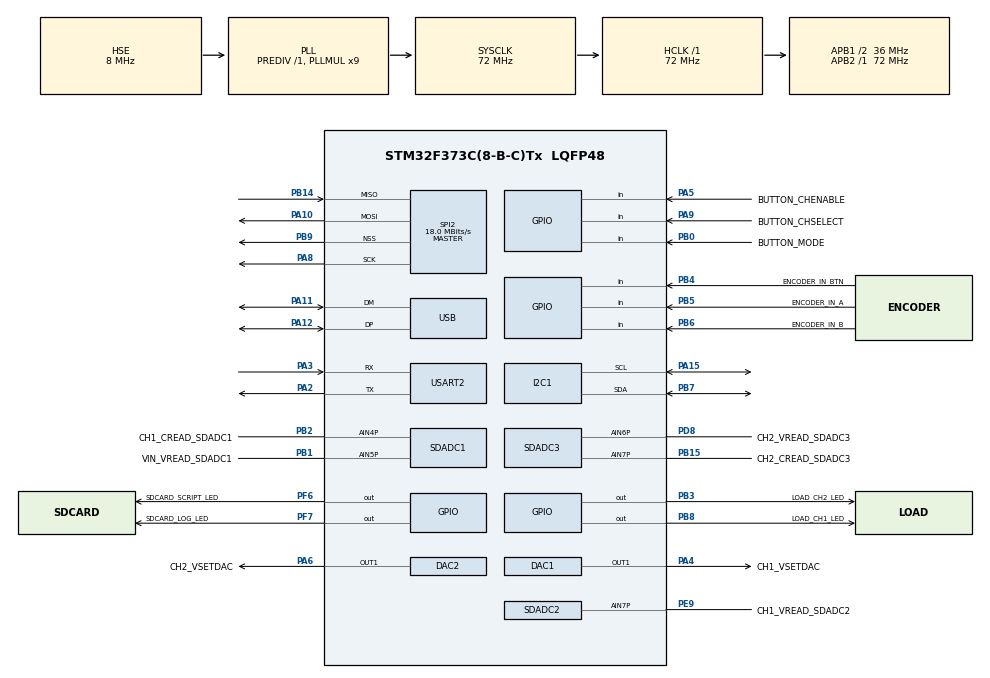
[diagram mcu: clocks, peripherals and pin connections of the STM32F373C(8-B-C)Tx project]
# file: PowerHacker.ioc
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ADC1.Channel-2\#ChannelRegularConversion=ADC_CHANNEL_TEMPSENSOR
ADC1.NbrOfConversion=1
ADC1.NbrOfConversionFlag=1
ADC1.Rank-2\#ChannelRegularConversion=1
ADC1.SamplingTime-2\#ChannelRegularConversion=ADC_SAMPLETIME_1CYCLE_5
ADC1.master=1
Mcu.Family=STM32F3
Mcu.Name=STM32F373C(8-B-C)Tx
Mcu.Package=LQFP48
NVIC.PriorityGroup=NVIC_PRIORITYGROUP_4
NVIC.TIM19_IRQn=true\:0\:0\:false\:false\:true\:false\:true
NVIC.TimeBase=TIM19_IRQn
NVIC.TimeBaseIP=TIM19
NVIC.USB_LP_IRQn=true\:0\:0\:false\:false\:true\:false\:true
PA10.Mode=Full_Duplex_Master
PA10.Signal=SPI2_MOSI
PA11.Mode=Device
PA11.Signal=USB_DM
PA12.Mode=Device
PA12.Signal=USB_DP
PA13.Mode=Serial_Wire
PA13.Signal=SYS_JTMS-SWDIO
PA14.Mode=Serial_Wire
PA14.Signal=SYS_JTCK-SWCLK
PA15.Mode=I2C
PA15.Signal=I2C1_SCL
PA2.Mode=Asynchronous
PA2.Signal=USART2_TX
PA3.Mode=Asynchronous
PA3.Signal=USART2_RX
PA4.GPIO_Label=CH1_VSETDAC
PA4.Signal=COMP_DAC11_group
PA5.GPIO_Label=BUTTON_CHENABLE
PA5.GPIO_PuPd=GPIO_PULLUP
PA5.Signal=GPIO_Input
PA6.GPIO_Label=CH2_VSETDAC
PA6.Signal=COMP_DAC21_group
PA8.Mode=Full_Duplex_Master
PA8.Signal=SPI2_SCK
PA9.GPIO_Label=BUTTON_CHSELECT
PA9.GPIO_PuPd=GPIO_PULLUP
PA9.Signal=GPIO_Input
PB0.GPIO_Label=BUTTON_MODE
PB0.GPIO_PuPd=GPIO_PULLUP
PB0.Signal=GPIO_Input
PB1.GPIO_Label=VIN_VREAD_SDADC1
PB1.Mode=IN5-Single-Ended
PB1.Signal=SDADC1_AIN5P
PB14.Mode=Full_Duplex_Master
PB14.Signal=SPI2_MISO
PB15.GPIO_Label=CH2_CREAD_SDADC3
PB15.Mode=IN7-Single-Ended
PB15.Signal=SDADC3_AIN7P
PB2.GPIO_Label=CH1_CREAD_SDADC1
PB2.Mode=IN4-Single-Ended
PB2.Signal=SDADC1_AIN4P
PB3.GPIO_Label=LOAD_CH2_LED
PB3.Signal=GPIO_Output
PB4.GPIO_Label=ENCODER_IN_BTN
PB4.GPIO_PuPd=GPIO_PULLUP
PB4.Signal=GPIO_Input
PB5.GPIO_Label=ENCODER_IN_A
PB5.GPIO_PuPd=GPIO_PULLUP
PB5.Signal=GPIO_Input
PB6.GPIO_Label=ENCODER_IN_B
PB6.GPIO_PuPd=GPIO_PULLUP
PB6.Signal=GPIO_Input
PB7.Mode=I2C
PB7.Signal=I2C1_SDA
PB8.GPIO_Label=LOAD_CH1_LED
PB8.Signal=GPIO_Output
PB9.Mode=NSS_Signal_Hard_Output
PB9.Signal=SPI2_NSS
PC14-OSC32_IN.Mode=LSE-External-Oscillator
PC14-OSC32_IN.Signal=RCC_OSC32_IN
PC15-OSC32_OUT.Mode=LSE-External-Oscillator
PC15-OSC32_OUT.Signal=RCC_OSC32_OUT
PD8.GPIO_Label=CH2_VREAD_SDADC3
PD8.Mode=IN6-Single-Ended
PD8.Signal=SDADC3_AIN6P
PE9.GPIO_Label=CH1_VREAD_SDADC2
PE9.Mode=IN7-Single-Ended
PE9.Signal=SDADC2_AIN7P
PF0-OSC_IN.Mode=HSE-External-Oscillator
PF0-OSC_IN.Signal=RCC_OSC_IN
PF1-OSC_OUT.Mode=HSE-External-Oscillator
PF1-OSC_OUT.Signal=RCC_OSC_OUT
PF6.GPIO_Label=SDCARD_SCRIPT_LED
PF6.Signal=GPIO_Output
PF7.GPIO_Label=SDCARD_LOG_LED
PF7.Signal=GPIO_Output
ProjectManager.HeapSize=0x200
ProjectManager.StackSize=0x400
ProjectManager.TargetToolchain=STM32CubeIDE
RCC.AHBFreq_Value=72000000
RCC.APB1CLKDivider=RCC_HCLK_DIV2
RCC.APB1Freq_Value=36000000
RCC.APB1TimFreq_Value=72000000
RCC.APB2Freq_Value=72000000
RCC.APB2TimFreq_Value=72000000
RCC.CortexFreq_Value=72000000
RCC.HCLKFreq_Value=72000000
RCC.HSE_VALUE=8000000
RCC.HSI_VALUE=8000000
RCC.PLLMUL=RCC_PLL_MUL9
RCC.PRESCALERUSB=RCC_USBCLKSOURCE_PLL_DIV1_5
RCC.RTCClockSelection=RCC_RTCCLKSOURCE_LSE
RCC.SDADCPresc=RCC_SDADCSYSCLK_DIV12
RCC.SYSCLKFreq_VALUE=72000000
RCC.SYSCLKSource=RCC_SYSCLKSOURCE_PLLCLK
RCC.USBFreq_Value=48000000
SDADC1.NbrOfConversionFlag=1
SDADC2.NbrOfConversionFlag=1
SDADC3.NbrOfConversionFlag=1
SH.COMP_DAC11_group.0=DAC1_OUT1,DAC_OUT1
SH.COMP_DAC21_group.0=DAC2_OUT1,DAC_OUT1
SPI2.CalculateBaudRate=18.0 MBits/s
SPI2.Direction=SPI_DIRECTION_2LINES
SPI2.Mode=SPI_MODE_MASTER
SPI2.VirtualNSS=VM_NSSHARD
SPI2.VirtualType=VM_MASTER
USART2.VirtualMode-Asynchronous=VM_ASYNC
USB_DEVICE.CLASS_NAME_FS=CDC
USB_DEVICE.LANGID_STRING=1033
USB_DEVICE.MANUFACTURER_STRING=ArduCore
USB_DEVICE.PRODUCT_STRING_CDC_FS=ArduCore PowerHacker
USB_DEVICE.VirtualMode=Cdc
USB_DEVICE.VirtualModeFS=Cdc_FS
VP_ADC1_TempSens_Input.Mode=IN-TempSens
VP_RTC_VS_RTC_Activate.Mode=RTC_Enabled
VP_SDADC1_CONF0.Mode=ConfigZero
VP_SDADC2_CONF1.Mode=ConfigUn
VP_SYS_VS_tim19.Mode=TIM19
VP_USB_DEVICE_VS_USB_DEVICE_CDC_FS.Mode=CDC_FS
board=custom

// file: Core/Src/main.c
/* USER CODE BEGIN Header */
/**
  ******************************************************************************
  * @file           : main.c
  * @brief          : Main program body
  ******************************************************************************
  * @attention
  *
  * <h2><center>&copy; Copyright (c) 2020 STMicroelectronics.
  * All rights reserved.</center></h2>
  *
  * This software component is licensed by ST under BSD 3-Clause license,
  * the "License"; You may not use this file except in compliance with the
  * License. You may obtain a copy of the License at:
  *                        opensource.org/licenses/BSD-3-Clause
  *
  ******************************************************************************
  */
/* USER CODE END Header */
#include "main.h"
#include "usb_device.h"

/* USER CODE BEGIN Includes */
#include <entryPointDefinition.hpp>
/* USER CODE END Includes */

ADC_HandleTypeDef hadc1;

DAC_HandleTypeDef hdac1;
DAC_HandleTypeDef hdac2;

I2C_HandleTypeDef hi2c1;

RTC_HandleTypeDef hrtc;

SDADC_HandleTypeDef hsdadc1;
SDADC_HandleTypeDef hsdadc2;
SDADC_HandleTypeDef hsdadc3;

SPI_HandleTypeDef hspi2;

UART_HandleTypeDef huart2;

void SystemClock_Config(void);
static void MX_GPIO_Init(void);
static void MX_I2C1_Init(void);
static void MX_RTC_Init(void);
static void MX_SDADC1_Init(void);
static void MX_ADC1_Init(void);
static void MX_DAC1_Init(void);
static void MX_DAC2_Init(void);
static void MX_SDADC2_Init(void);
static void MX_SPI2_Init(void);
static void MX_SDADC3_Init(void);
static void MX_USART2_UART_Init(void);

int main(void)
{

  /* MCU Configuration--------------------------------------------------------*/

  /* Reset of all peripherals, Initializes the Flash interface and the Systick. */
  HAL_Init();

  /* Configure the system clock */
  SystemClock_Config();

  /* Initialize all configured peripherals */
  MX_GPIO_Init();
  MX_I2C1_Init();
  MX_RTC_Init();
  MX_SDADC1_Init();
  MX_ADC1_Init();
  MX_DAC1_Init();
  MX_DAC2_Init();
  MX_SDADC2_Init();
  MX_SPI2_Init();
  MX_USB_DEVICE_Init();
  MX_SDADC3_Init();
  MX_USART2_UART_Init();
  /* USER CODE BEGIN 2 */
  HAL_DAC_Start(&hdac1, DAC_CHANNEL_1);
  HAL_DAC_SetValue(&hdac1, DAC_CHANNEL_1, DAC_ALIGN_12B_L, 0x100); //TODO: Debug DAC values
  entryPointSetup();
  /* USER CODE END 2 */

  /* Infinite loop */
  for(;;)
  {

    /* USER CODE BEGIN 3 */
	  entryPointLoop();

  }
  /* USER CODE END 3 */
}

void SystemClock_Config(void)
{
  RCC_OscInitTypeDef RCC_OscInitStruct = {0};
  RCC_ClkInitTypeDef RCC_ClkInitStruct = {0};
  RCC_PeriphCLKInitTypeDef PeriphClkInit = {0};

  /** Configure LSE Drive Capability
  */
  HAL_PWR_EnableBkUpAccess();
  __HAL_RCC_LSEDRIVE_CONFIG(RCC_LSEDRIVE_LOW);
  /** Initializes the RCC Oscillators according to the specified parameters
  * in the RCC_OscInitTypeDef structure.
  */
  RCC_OscInitStruct.OscillatorType = RCC_OSCILLATORTYPE_HSI|RCC_OSCILLATORTYPE_HSE
                              |RCC_OSCILLATORTYPE_LSE;
  RCC_OscInitStruct.HSEState = RCC_HSE_ON;
  RCC_OscInitStruct.HSEPredivValue = RCC_HSE_PREDIV_DIV1;
  RCC_OscInitStruct.LSEState = RCC_LSE_ON;
  RCC_OscInitStruct.HSIState = RCC_HSI_ON;
  RCC_OscInitStruct.HSICalibrationValue = RCC_HSICALIBRATION_DEFAULT;
  RCC_OscInitStruct.PLL.PLLState = RCC_PLL_ON;
  RCC_OscInitStruct.PLL.PLLSource = RCC_PLLSOURCE_HSE;
  RCC_OscInitStruct.PLL.PLLMUL = RCC_PLL_MUL9;
  if (HAL_RCC_OscConfig(&RCC_OscInitStruct) != HAL_OK)
  {
    Error_Handler();
  }
  /** Initializes the CPU, AHB and APB buses clocks
  */
  RCC_ClkInitStruct.ClockType = RCC_CLOCKTYPE_HCLK|RCC_CLOCKTYPE_SYSCLK
                              |RCC_CLOCKTYPE_PCLK1|RCC_CLOCKTYPE_PCLK2;
  RCC_ClkInitStruct.SYSCLKSource = RCC_SYSCLKSOURCE_PLLCLK;
  RCC_ClkInitStruct.AHBCLKDivider = RCC_SYSCLK_DIV1;
  RCC_ClkInitStruct.APB1CLKDivider = RCC_HCLK_DIV2;
  RCC_ClkInitStruct.APB2CLKDivider = RCC_HCLK_DIV1;

  if (HAL_RCC_ClockConfig(&RCC_ClkInitStruct, FLASH_LATENCY_2) != HAL_OK)
  {
    Error_Handler();
  }
  PeriphClkInit.PeriphClockSelection = RCC_PERIPHCLK_USB|RCC_PERIPHCLK_USART2
                              |RCC_PERIPHCLK_I2C1|RCC_PERIPHCLK_RTC
                              |RCC_PERIPHCLK_ADC1|RCC_PERIPHCLK_SDADC;
  PeriphClkInit.Usart2ClockSelection = RCC_USART2CLKSOURCE_PCLK1;
  PeriphClkInit.I2c1ClockSelection = RCC_I2C1CLKSOURCE_HSI;
  PeriphClkInit.RTCClockSelection = RCC_RTCCLKSOURCE_LSE;
  PeriphClkInit.USBClockSelection = RCC_USBCLKSOURCE_PLL_DIV1_5;
  PeriphClkInit.SdadcClockSelection = RCC_SDADCSYSCLK_DIV12;
  PeriphClkInit.Adc1ClockSelection = RCC_ADC1PCLK2_DIV2;

  if (HAL_RCCEx_PeriphCLKConfig(&PeriphClkInit) != HAL_OK)
  {
    Error_Handler();
  }
  HAL_PWREx_EnableSDADC(PWR_SDADC_ANALOG1);
  HAL_PWREx_EnableSDADC(PWR_SDADC_ANALOG2);
  HAL_PWREx_EnableSDADC(PWR_SDADC_ANALOG3);
}

static void MX_ADC1_Init(void)
{

  ADC_ChannelConfTypeDef sConfig = {0};

  /** Common config
  */
  hadc1.Instance = ADC1;
  hadc1.Init.ScanConvMode = ADC_SCAN_DISABLE;
  hadc1.Init.ContinuousConvMode = DISABLE;
  hadc1.Init.DiscontinuousConvMode = DISABLE;
  hadc1.Init.ExternalTrigConv = ADC_SOFTWARE_START;
  hadc1.Init.DataAlign = ADC_DATAALIGN_RIGHT;
  hadc1.Init.NbrOfConversion = 1;
  if (HAL_ADC_Init(&hadc1) != HAL_OK)
  {
    Error_Handler();
  }
  /** Configure Regular Channel
  */
  sConfig.Channel = ADC_CHANNEL_TEMPSENSOR;
  sConfig.Rank = ADC_REGULAR_RANK_1;
  sConfig.SamplingTime = ADC_SAMPLETIME_1CYCLE_5;
  if (HAL_ADC_ConfigChannel(&hadc1, &sConfig) != HAL_OK)
  {
    Error_Handler();
  }

}

static void MX_DAC1_Init(void)
{

  DAC_ChannelConfTypeDef sConfig = {0};

  /** DAC Initialization
  */
  hdac1.Instance = DAC1;
  if (HAL_DAC_Init(&hdac1) != HAL_OK)
  {
    Error_Handler();
  }
  /** DAC channel OUT1 config
  */
  sConfig.DAC_Trigger = DAC_TRIGGER_NONE;
  sConfig.DAC_OutputBuffer = DAC_OUTPUTBUFFER_ENABLE;
  if (HAL_DAC_ConfigChannel(&hdac1, &sConfig, DAC_CHANNEL_1) != HAL_OK)
  {
    Error_Handler();
  }

}

static void MX_DAC2_Init(void)
{

  DAC_ChannelConfTypeDef sConfig = {0};

  /** DAC Initialization
  */
  hdac2.Instance = DAC2;
  if (HAL_DAC_Init(&hdac2) != HAL_OK)
  {
    Error_Handler();
  }
  /** DAC channel OUT1 config
  */
  sConfig.DAC_Trigger = DAC_TRIGGER_NONE;
  sConfig.DAC_OutputBuffer = DAC_OUTPUTBUFFER_ENABLE;
  if (HAL_DAC_ConfigChannel(&hdac2, &sConfig, DAC_CHANNEL_1) != HAL_OK)
  {
    Error_Handler();
  }

}

static void MX_I2C1_Init(void)
{

  hi2c1.Instance = I2C1;
  hi2c1.Init.Timing = 0x2000090E;
  hi2c1.Init.OwnAddress1 = 0;
  hi2c1.Init.AddressingMode = I2C_ADDRESSINGMODE_7BIT;
  hi2c1.Init.DualAddressMode = I2C_DUALADDRESS_DISABLE;
  hi2c1.Init.OwnAddress2 = 0;
  hi2c1.Init.OwnAddress2Masks = I2C_OA2_NOMASK;
  hi2c1.Init.GeneralCallMode = I2C_GENERALCALL_DISABLE;
  hi2c1.Init.NoStretchMode = I2C_NOSTRETCH_DISABLE;
  if (HAL_I2C_Init(&hi2c1) != HAL_OK)
  {
    Error_Handler();
  }
  /** Configure Analogue filter
  */
  if (HAL_I2CEx_ConfigAnalogFilter(&hi2c1, I2C_ANALOGFILTER_ENABLE) != HAL_OK)
  {
    Error_Handler();
  }
  /** Configure Digital filter
  */
  if (HAL_I2CEx_ConfigDigitalFilter(&hi2c1, 0) != HAL_OK)
  {
    Error_Handler();
  }

}

static void MX_RTC_Init(void)
{

  /** Initialize RTC Only
  */
  hrtc.Instance = RTC;
  hrtc.Init.HourFormat = RTC_HOURFORMAT_24;
  hrtc.Init.AsynchPrediv = 127;
  hrtc.Init.SynchPrediv = 255;
  hrtc.Init.OutPut = RTC_OUTPUT_DISABLE;
  hrtc.Init.OutPutPolarity = RTC_OUTPUT_POLARITY_HIGH;
  hrtc.Init.OutPutType = RTC_OUTPUT_TYPE_OPENDRAIN;
  if (HAL_RTC_Init(&hrtc) != HAL_OK)
  {
    Error_Handler();
  }

}

static void MX_SDADC1_Init(void)
{

  SDADC_ConfParamTypeDef ConfParamStruct = {0};

  /** Configure the SDADC low power mode, fast conversion mode,
  slow clock mode and SDADC1 reference voltage
  */
  hsdadc1.Instance = SDADC1;
  hsdadc1.Init.IdleLowPowerMode = SDADC_LOWPOWER_NONE;
  hsdadc1.Init.FastConversionMode = SDADC_FAST_CONV_DISABLE;
  hsdadc1.Init.SlowClockMode = SDADC_SLOW_CLOCK_DISABLE;
  hsdadc1.Init.ReferenceVoltage = SDADC_VREF_EXT;
  if (HAL_SDADC_Init(&hsdadc1) != HAL_OK)
  {
    Error_Handler();
  }
  /** Set parameters for SDADC configuration 0 Register
  */
  ConfParamStruct.InputMode = SDADC_INPUT_MODE_DIFF;
  ConfParamStruct.Gain = SDADC_GAIN_1;
  ConfParamStruct.CommonMode = SDADC_COMMON_MODE_VSSA;
  ConfParamStruct.Offset = 0;
  if (HAL_SDADC_PrepareChannelConfig(&hsdadc1, SDADC_CONF_INDEX_0, &ConfParamStruct) != HAL_OK)
  {
    Error_Handler();
  }

}

static void MX_SDADC2_Init(void)
{

  SDADC_ConfParamTypeDef ConfParamStruct = {0};

  /** Configure the SDADC low power mode, fast conversion mode,
  slow clock mode and SDADC1 reference voltage
  */
  hsdadc2.Instance = SDADC2;
  hsdadc2.Init.IdleLowPowerMode = SDADC_LOWPOWER_NONE;
  hsdadc2.Init.FastConversionMode = SDADC_FAST_CONV_DISABLE;
  hsdadc2.Init.SlowClockMode = SDADC_SLOW_CLOCK_DISABLE;
  hsdadc2.Init.ReferenceVoltage = SDADC_VREF_EXT;
  if (HAL_SDADC_Init(&hsdadc2) != HAL_OK)
  {
    Error_Handler();
  }
  /** Set parameters for SDADC configuration 1 Register
  */
  ConfParamStruct.InputMode = SDADC_INPUT_MODE_DIFF;
  ConfParamStruct.Gain = SDADC_GAIN_1;
  ConfParamStruct.CommonMode = SDADC_COMMON_MODE_VSSA;
  ConfParamStruct.Offset = 0;
  if (HAL_SDADC_PrepareChannelConfig(&hsdadc2, SDADC_CONF_INDEX_1, &ConfParamStruct) != HAL_OK)
  {
    Error_Handler();
  }

}

static void MX_SDADC3_Init(void)
{

  /** Configure the SDADC low power mode, fast conversion mode,
  slow clock mode and SDADC1 reference voltage
  */
  hsdadc3.Instance = SDADC3;
  hsdadc3.Init.IdleLowPowerMode = SDADC_LOWPOWER_NONE;
  hsdadc3.Init.FastConversionMode = SDADC_FAST_CONV_DISABLE;
  hsdadc3.Init.SlowClockMode = SDADC_SLOW_CLOCK_DISABLE;
  hsdadc3.Init.ReferenceVoltage = SDADC_VREF_EXT;
  if (HAL_SDADC_Init(&hsdadc3) != HAL_OK)
  {
    Error_Handler();
  }

}

static void MX_SPI2_Init(void)
{

  /* SPI2 parameter configuration*/
  hspi2.Instance = SPI2;
  hspi2.Init.Mode = SPI_MODE_MASTER;
  hspi2.Init.Direction = SPI_DIRECTION_2LINES;
  hspi2.Init.DataSize = SPI_DATASIZE_4BIT;
  hspi2.Init.CLKPolarity = SPI_POLARITY_LOW;
  hspi2.Init.CLKPhase = SPI_PHASE_1EDGE;
  hspi2.Init.NSS = SPI_NSS_HARD_OUTPUT;
  hspi2.Init.BaudRatePrescaler = SPI_BAUDRATEPRESCALER_2;
  hspi2.Init.FirstBit = SPI_FIRSTBIT_MSB;
  hspi2.Init.TIMode = SPI_TIMODE_DISABLE;
  hspi2.Init.CRCCalculation = SPI_CRCCALCULATION_DISABLE;
  hspi2.Init.CRCPolynomial = 7;
  hspi2.Init.CRCLength = SPI_CRC_LENGTH_DATASIZE;
  hspi2.Init.NSSPMode = SPI_NSS_PULSE_ENABLE;
  if (HAL_SPI_Init(&hspi2) != HAL_OK)
  {
    Error_Handler();
  }

}

static void MX_USART2_UART_Init(void)
{

  huart2.Instance = USART2;
  huart2.Init.BaudRate = 38400;
  huart2.Init.WordLength = UART_WORDLENGTH_8B;
  huart2.Init.StopBits = UART_STOPBITS_1;
  huart2.Init.Parity = UART_PARITY_NONE;
  huart2.Init.Mode = UART_MODE_TX_RX;
  huart2.Init.HwFlowCtl = UART_HWCONTROL_NONE;
  huart2.Init.OverSampling = UART_OVERSAMPLING_16;
  huart2.Init.OneBitSampling = UART_ONE_BIT_SAMPLE_DISABLE;
  huart2.AdvancedInit.AdvFeatureInit = UART_ADVFEATURE_NO_INIT;
  if (HAL_UART_Init(&huart2) != HAL_OK)
  {
    Error_Handler();
  }

}

static void MX_GPIO_Init(void)
{
  GPIO_InitTypeDef GPIO_InitStruct = {0};

  /* GPIO Ports Clock Enable */
  __HAL_RCC_GPIOC_CLK_ENABLE();
  __HAL_RCC_GPIOF_CLK_ENABLE();
  __HAL_RCC_GPIOA_CLK_ENABLE();
  __HAL_RCC_GPIOB_CLK_ENABLE();
  __HAL_RCC_GPIOE_CLK_ENABLE();
  __HAL_RCC_GPIOD_CLK_ENABLE();

  /*Configure GPIO pin Output Level */
  HAL_GPIO_WritePin(GPIOF, SDCARD_SCRIPT_LED_Pin|SDCARD_LOG_LED_Pin, GPIO_PIN_RESET);

  /*Configure GPIO pin Output Level */
  HAL_GPIO_WritePin(GPIOB, LOAD_CH2_LED_Pin|LOAD_CH1_LED_Pin, GPIO_PIN_RESET);

  /*Configure GPIO pins : BUTTON_CHENABLE_Pin BUTTON_CHSELECT_Pin */
  GPIO_InitStruct.Pin = BUTTON_CHENABLE_Pin|BUTTON_CHSELECT_Pin;
  GPIO_InitStruct.Mode = GPIO_MODE_INPUT;
  GPIO_InitStruct.Pull = GPIO_PULLUP;
  HAL_GPIO_Init(GPIOA, &GPIO_InitStruct);

  /*Configure GPIO pins : BUTTON_MODE_Pin ENCODER_IN_BTN_Pin ENCODER_IN_A_Pin ENCODER_IN_B_Pin */
  GPIO_InitStruct.Pin = BUTTON_MODE_Pin|ENCODER_IN_BTN_Pin|ENCODER_IN_A_Pin|ENCODER_IN_B_Pin;
  GPIO_InitStruct.Mode = GPIO_MODE_INPUT;
  GPIO_InitStruct.Pull = GPIO_PULLUP;
  HAL_GPIO_Init(GPIOB, &GPIO_InitStruct);

  /*Configure GPIO pins : SDCARD_SCRIPT_LED_Pin SDCARD_LOG_LED_Pin */
  GPIO_InitStruct.Pin = SDCARD_SCRIPT_LED_Pin|SDCARD_LOG_LED_Pin;
  GPIO_InitStruct.Mode = GPIO_MODE_OUTPUT_PP;
  GPIO_InitStruct.Pull = GPIO_NOPULL;
  GPIO_InitStruct.Speed = GPIO_SPEED_FREQ_LOW;
  HAL_GPIO_Init(GPIOF, &GPIO_InitStruct);

  /*Configure GPIO pins : LOAD_CH2_LED_Pin LOAD_CH1_LED_Pin */
  GPIO_InitStruct.Pin = LOAD_CH2_LED_Pin|LOAD_CH1_LED_Pin;
  GPIO_InitStruct.Mode = GPIO_MODE_OUTPUT_PP;
  GPIO_InitStruct.Pull = GPIO_NOPULL;
  GPIO_InitStruct.Speed = GPIO_SPEED_FREQ_LOW;
  HAL_GPIO_Init(GPIOB, &GPIO_InitStruct);

}

 /**
  * @brief  Period elapsed callback in non blocking mode
  * @note   This function is called  when TIM19 interrupt took place, inside
  * HAL_TIM_IRQHandler(). It makes a direct call to HAL_IncTick() to increment
  * a global variable "uwTick" used as application time base.
  * @param  htim : TIM handle
  * @retval None
  */
void HAL_TIM_PeriodElapsedCallback(TIM_HandleTypeDef *htim)
{
  if (htim->Instance == TIM19) {
    HAL_IncTick();
  }
}

void Error_Handler(void)
{
}

/************************ (C) COPYRIGHT STMicroelectronics *****END OF FILE****/
